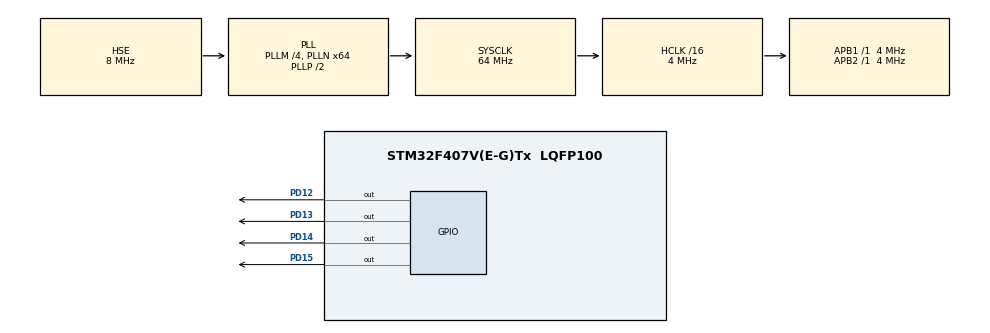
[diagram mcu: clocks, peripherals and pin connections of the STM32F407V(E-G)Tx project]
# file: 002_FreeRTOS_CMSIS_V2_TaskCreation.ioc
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FREERTOS.Tasks01=defaultTask,24,128,StartDefaultTask,Default,NULL,Dynamic,NULL,NULL
Mcu.Family=STM32F4
Mcu.Name=STM32F407V(E-G)Tx
Mcu.Package=LQFP100
NVIC.PriorityGroup=NVIC_PRIORITYGROUP_4
NVIC.TIM6_DAC_IRQn=true\:15\:0\:false\:false\:true\:false\:false\:true\:true
NVIC.TimeBase=TIM6_DAC_IRQn
NVIC.TimeBaseIP=TIM6
PD12.Signal=GPIO_Output
PD13.Signal=GPIO_Output
PD14.Signal=GPIO_Output
PD15.Signal=GPIO_Output
PH0-OSC_IN.Mode=HSE-External-Oscillator
PH0-OSC_IN.Signal=RCC_OSC_IN
PH1-OSC_OUT.Mode=HSE-External-Oscillator
PH1-OSC_OUT.Signal=RCC_OSC_OUT
ProjectManager.HeapSize=0x200
ProjectManager.StackSize=0x400
ProjectManager.TargetToolchain=STM32CubeIDE
RCC.48MHZClocksFreq_Value=18285714.285714287
RCC.AHBCLKDivider=RCC_SYSCLK_DIV16
RCC.AHBFreq_Value=4000000
RCC.APB1Freq_Value=4000000
RCC.APB1TimFreq_Value=4000000
RCC.APB2Freq_Value=4000000
RCC.APB2TimFreq_Value=4000000
RCC.CortexFreq_Value=4000000
RCC.HCLKFreq_Value=4000000
RCC.HSE_VALUE=8000000
RCC.HSI_VALUE=16000000
RCC.PLLM=4
RCC.PLLN=64
RCC.PLLQ=7
RCC.PLLSourceVirtual=RCC_PLLSOURCE_HSE
RCC.SYSCLKFreq_VALUE=64000000
RCC.SYSCLKSource=RCC_SYSCLKSOURCE_PLLCLK
RCC.VCOOutputFreq_Value=128000000
VP_FREERTOS_VS_CMSIS_V2.Mode=CMSIS_V2
VP_SYS_VS_tim6.Mode=TIM6
board=STM32F407G-DISC1

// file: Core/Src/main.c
/* USER CODE BEGIN Header */
/**
  ******************************************************************************
  * @file           : main.c
  * @brief          : Main program body
  ******************************************************************************
  * @attention
  *
  * Copyright (c) 2023 STMicroelectronics.
  * All rights reserved.
  *
  * This software is licensed under terms that can be found in the LICENSE file
  * in the root directory of this software component.
  * If no LICENSE file comes with this software, it is provided AS-IS.
  *
  ******************************************************************************
  */
/* USER CODE END Header */
#include "main.h"
#include "cmsis_os.h"

/* USER CODE BEGIN PM */
osThreadId_t Task1Handle = NULL;
/* USER CODE END PM */

/* Definitions for defaultTask */
osThreadId_t defaultTaskHandle;
const osThreadAttr_t defaultTask_attributes = {
  .name = "defaultTask",
  .stack_size = 128 * 4,
  .priority = (osPriority_t) osPriorityNormal,
};

void SystemClock_Config(void);
static void MX_GPIO_Init(void);
void StartDefaultTask(void *argument);

/* USER CODE BEGIN 0 */
void blinkThread(void *pvParameters)
{
	for(;;)
	{
		HAL_GPIO_TogglePin(GPIOD, GPIO_PIN_12);
		osDelay(500);
	}
}
/* USER CODE END 0 */

int main(void)
{

  /* MCU Configuration--------------------------------------------------------*/

  /* Reset of all peripherals, Initializes the Flash interface and the Systick. */
  HAL_Init();

  /* Configure the system clock */
  SystemClock_Config();

  /* Initialize all configured peripherals */
  MX_GPIO_Init();
  /* USER CODE BEGIN 2 */
  const osThreadAttr_t Task1_attr = {
		  .name = "Task1",
		  .stack_size = 1000,
		  .priority = (osPriority_t)osPriorityNormal
  };
  Task1Handle = osThreadNew(blinkThread,NULL,&Task1_attr);
  /* USER CODE END 2 */

  /* Init scheduler */
  osKernelInitialize();

  /* Create the thread(s) */
  /* creation of defaultTask */
  defaultTaskHandle = osThreadNew(StartDefaultTask, NULL, &defaultTask_attributes);

  /* Start scheduler */
  osKernelStart();
  /* We should never get here as control is now taken by the scheduler */
  /* Infinite loop */
  while (1)
  {

  }
}

void SystemClock_Config(void)
{
  RCC_OscInitTypeDef RCC_OscInitStruct = {0};
  RCC_ClkInitTypeDef RCC_ClkInitStruct = {0};

  /** Configure the main internal regulator output voltage
  */
  __HAL_RCC_PWR_CLK_ENABLE();
  __HAL_PWR_VOLTAGESCALING_CONFIG(PWR_REGULATOR_VOLTAGE_SCALE1);

  /** Initializes the RCC Oscillators according to the specified parameters
  * in the RCC_OscInitTypeDef structure.
  */
  RCC_OscInitStruct.OscillatorType = RCC_OSCILLATORTYPE_HSE;
  RCC_OscInitStruct.HSEState = RCC_HSE_ON;
  RCC_OscInitStruct.PLL.PLLState = RCC_PLL_ON;
  RCC_OscInitStruct.PLL.PLLSource = RCC_PLLSOURCE_HSE;
  RCC_OscInitStruct.PLL.PLLM = 4;
  RCC_OscInitStruct.PLL.PLLN = 64;
  RCC_OscInitStruct.PLL.PLLP = RCC_PLLP_DIV2;
  RCC_OscInitStruct.PLL.PLLQ = 7;
  if (HAL_RCC_OscConfig(&RCC_OscInitStruct) != HAL_OK)
  {
    Error_Handler();
  }

  /** Initializes the CPU, AHB and APB buses clocks
  */
  RCC_ClkInitStruct.ClockType = RCC_CLOCKTYPE_HCLK|RCC_CLOCKTYPE_SYSCLK
                              |RCC_CLOCKTYPE_PCLK1|RCC_CLOCKTYPE_PCLK2;
  RCC_ClkInitStruct.SYSCLKSource = RCC_SYSCLKSOURCE_PLLCLK;
  RCC_ClkInitStruct.AHBCLKDivider = RCC_SYSCLK_DIV16;
  RCC_ClkInitStruct.APB1CLKDivider = RCC_HCLK_DIV1;
  RCC_ClkInitStruct.APB2CLKDivider = RCC_HCLK_DIV1;

  if (HAL_RCC_ClockConfig(&RCC_ClkInitStruct, FLASH_LATENCY_0) != HAL_OK)
  {
    Error_Handler();
  }
}

static void MX_GPIO_Init(void)
{
  GPIO_InitTypeDef GPIO_InitStruct = {0};

  /* GPIO Ports Clock Enable */
  __HAL_RCC_GPIOH_CLK_ENABLE();
  __HAL_RCC_GPIOD_CLK_ENABLE();

  /*Configure GPIO pin Output Level */
  HAL_GPIO_WritePin(GPIOD, GPIO_PIN_12|GPIO_PIN_13|GPIO_PIN_14|GPIO_PIN_15, GPIO_PIN_RESET);

  /*Configure GPIO pins : PD12 PD13 PD14 PD15 */
  GPIO_InitStruct.Pin = GPIO_PIN_12|GPIO_PIN_13|GPIO_PIN_14|GPIO_PIN_15;
  GPIO_InitStruct.Mode = GPIO_MODE_OUTPUT_PP;
  GPIO_InitStruct.Pull = GPIO_NOPULL;
  GPIO_InitStruct.Speed = GPIO_SPEED_FREQ_LOW;
  HAL_GPIO_Init(GPIOD, &GPIO_InitStruct);

}

void StartDefaultTask(void *argument)
{
  for(;;)
  {
    osDelay(1);
  }
}

void HAL_TIM_PeriodElapsedCallback(TIM_HandleTypeDef *htim)
{
  if (htim->Instance == TIM6) {
    HAL_IncTick();
  }
}

void Error_Handler(void)
{
  __disable_irq();
  while (1)
  {
  }
}
